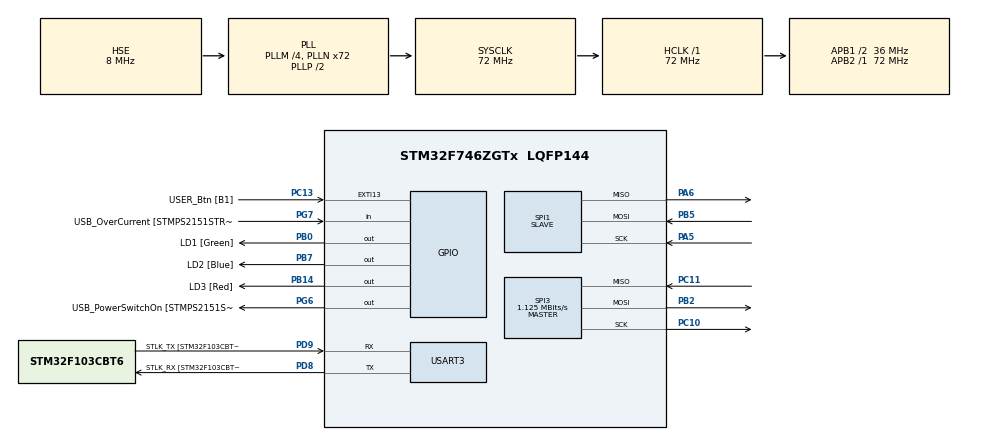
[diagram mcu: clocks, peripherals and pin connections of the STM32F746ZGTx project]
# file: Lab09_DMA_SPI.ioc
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Dma.Request0=SPI1_RX
Dma.Request1=SPI1_TX
Dma.Request2=SPI3_RX
Dma.Request3=SPI3_TX
Dma.SPI1_RX.0.Direction=DMA_PERIPH_TO_MEMORY
Dma.SPI1_RX.0.FIFOMode=DMA_FIFOMODE_DISABLE
Dma.SPI1_RX.0.Instance=DMA2_Stream0
Dma.SPI1_RX.0.MemDataAlignment=DMA_MDATAALIGN_BYTE
Dma.SPI1_RX.0.MemInc=DMA_MINC_ENABLE
Dma.SPI1_RX.0.Mode=DMA_NORMAL
Dma.SPI1_RX.0.PeriphDataAlignment=DMA_PDATAALIGN_BYTE
Dma.SPI1_RX.0.PeriphInc=DMA_PINC_DISABLE
Dma.SPI1_RX.0.Priority=DMA_PRIORITY_LOW
Dma.SPI1_TX.1.Direction=DMA_MEMORY_TO_PERIPH
Dma.SPI1_TX.1.FIFOMode=DMA_FIFOMODE_DISABLE
Dma.SPI1_TX.1.Instance=DMA2_Stream3
Dma.SPI1_TX.1.MemDataAlignment=DMA_MDATAALIGN_BYTE
Dma.SPI1_TX.1.MemInc=DMA_MINC_ENABLE
Dma.SPI1_TX.1.Mode=DMA_NORMAL
Dma.SPI1_TX.1.PeriphDataAlignment=DMA_PDATAALIGN_BYTE
Dma.SPI1_TX.1.PeriphInc=DMA_PINC_DISABLE
Dma.SPI1_TX.1.Priority=DMA_PRIORITY_LOW
Dma.SPI3_RX.2.Direction=DMA_PERIPH_TO_MEMORY
Dma.SPI3_RX.2.FIFOMode=DMA_FIFOMODE_DISABLE
Dma.SPI3_RX.2.Instance=DMA1_Stream0
Dma.SPI3_RX.2.MemDataAlignment=DMA_MDATAALIGN_BYTE
Dma.SPI3_RX.2.MemInc=DMA_MINC_ENABLE
Dma.SPI3_RX.2.Mode=DMA_NORMAL
Dma.SPI3_RX.2.PeriphDataAlignment=DMA_PDATAALIGN_BYTE
Dma.SPI3_RX.2.PeriphInc=DMA_PINC_DISABLE
Dma.SPI3_RX.2.Priority=DMA_PRIORITY_LOW
Dma.SPI3_TX.3.Direction=DMA_MEMORY_TO_PERIPH
Dma.SPI3_TX.3.FIFOMode=DMA_FIFOMODE_DISABLE
Dma.SPI3_TX.3.Instance=DMA1_Stream5
Dma.SPI3_TX.3.MemDataAlignment=DMA_MDATAALIGN_BYTE
Dma.SPI3_TX.3.MemInc=DMA_MINC_ENABLE
Dma.SPI3_TX.3.Mode=DMA_NORMAL
Dma.SPI3_TX.3.PeriphDataAlignment=DMA_PDATAALIGN_BYTE
Dma.SPI3_TX.3.PeriphInc=DMA_PINC_DISABLE
Dma.SPI3_TX.3.Priority=DMA_PRIORITY_LOW
Mcu.Family=STM32F7
Mcu.Name=STM32F746ZGTx
Mcu.Package=LQFP144
NVIC.DMA1_Stream0_IRQn=true\:0\:0\:false\:false\:true\:false\:true\:true
NVIC.DMA1_Stream5_IRQn=true\:0\:0\:false\:false\:true\:false\:true\:true
NVIC.DMA2_Stream0_IRQn=true\:0\:0\:false\:false\:true\:false\:true\:true
NVIC.DMA2_Stream3_IRQn=true\:0\:0\:false\:false\:true\:false\:true\:true
NVIC.PriorityGroup=NVIC_PRIORITYGROUP_4
NVIC.SPI1_IRQn=true\:0\:0\:true\:false\:true\:true\:true\:true
NVIC.SPI3_IRQn=true\:0\:0\:false\:false\:true\:true\:true\:true
PA13.GPIO_Label=TMS
PA13.Mode=Serial_Wire
PA13.Signal=SYS_JTMS-SWDIO
PA14.GPIO_Label=TCK
PA14.Mode=Serial_Wire
PA14.Signal=SYS_JTCK-SWCLK
PA5.Mode=Full_Duplex_Slave
PA5.Signal=SPI1_SCK
PA6.Mode=Full_Duplex_Slave
PA6.Signal=SPI1_MISO
PB0.GPIO_Label=LD1 [Green]
PB0.Signal=GPIO_Output
PB14.GPIO_Label=LD3 [Red]
PB14.Signal=GPIO_Output
PB2.Mode=Full_Duplex_Master
PB2.Signal=SPI3_MOSI
PB3.GPIO_Label=SW0
PB3.Signal=SYS_JTDO-SWO
PB5.Mode=Full_Duplex_Slave
PB5.Signal=SPI1_MOSI
PB7.GPIO_Label=LD2 [Blue]
PB7.Signal=GPIO_Output
PC10.Mode=Full_Duplex_Master
PC10.Signal=SPI3_SCK
PC11.Mode=Full_Duplex_Master
PC11.Signal=SPI3_MISO
PC13.GPIO_Label=USER_Btn [B1]
PC13.Signal=GPXTI13
PC14/OSC32_IN.Mode=LSE-External-Oscillator
PC14/OSC32_IN.Signal=RCC_OSC32_IN
PC15/OSC32_OUT.Mode=LSE-External-Oscillator
PC15/OSC32_OUT.Signal=RCC_OSC32_OUT
PD8.GPIO_Label=STLK_RX [STM32F103CBT6_PA3]
PD8.GPIO_PuPd=GPIO_PULLUP
PD8.Mode=Asynchronous
PD8.Signal=USART3_TX
PD9.GPIO_Label=STLK_TX [STM32F103CBT6_PA2]
PD9.GPIO_PuPd=GPIO_PULLUP
PD9.Mode=Asynchronous
PD9.Signal=USART3_RX
PG6.GPIO_Label=USB_PowerSwitchOn [STMPS2151STR_EN]
PG6.Signal=GPIO_Output
PG7.GPIO_Label=USB_OverCurrent [STMPS2151STR_FAULT]
PG7.Signal=GPIO_Input
PH0/OSC_IN.GPIO_Label=MCO [STM32F103CBT6_PA8]
PH0/OSC_IN.Mode=HSE-External-Clock-Source
PH0/OSC_IN.Signal=RCC_OSC_IN
PH1/OSC_OUT.Mode=HSE-External-Clock-Source
PH1/OSC_OUT.Signal=RCC_OSC_OUT
ProjectManager.HeapSize=0x200
ProjectManager.StackSize=0x400
ProjectManager.TargetToolchain=STM32CubeIDE
RCC.48MHZClocksFreq_Value=24000000
RCC.AHBFreq_Value=72000000
RCC.APB1CLKDivider=RCC_HCLK_DIV2
RCC.APB1Freq_Value=36000000
RCC.APB1TimFreq_Value=72000000
RCC.APB2Freq_Value=72000000
RCC.APB2TimFreq_Value=72000000
RCC.CortexFreq_Value=72000000
RCC.HCLKFreq_Value=72000000
RCC.HSE_VALUE=8000000
RCC.HSI_VALUE=16000000
RCC.PLLM=4
RCC.PLLMUL=RCC_PLL_MUL9
RCC.PLLN=72
RCC.PLLQ=3
RCC.PLLSourceVirtual=RCC_PLLSOURCE_HSE
RCC.PRESCALERUSB=RCC_USBCLKSOURCE_PLL_DIV1_5
RCC.SYSCLKFreq_VALUE=72000000
RCC.SYSCLKSource=RCC_SYSCLKSOURCE_PLLCLK
RCC.SYSCLKSourceVirtual=RCC_SYSCLKSOURCE_PLLCLK
RCC.USBFreq_Value=48000000
RCC.VCOOutputFreq_Value=144000000
SPI1.DataSize=SPI_DATASIZE_8BIT
SPI1.Direction=SPI_DIRECTION_2LINES
SPI1.Mode=SPI_MODE_SLAVE
SPI1.VirtualType=VM_SLAVE
SPI3.BaudRatePrescaler=SPI_BAUDRATEPRESCALER_32
SPI3.CalculateBaudRate=1.125 MBits/s
SPI3.DataSize=SPI_DATASIZE_8BIT
SPI3.Direction=SPI_DIRECTION_2LINES
SPI3.Mode=SPI_MODE_MASTER
SPI3.VirtualType=VM_MASTER
USART3.VirtualMode-Asynchronous=VM_ASYNC
board=NUCLEO-F746ZG

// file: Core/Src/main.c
/* USER CODE BEGIN Header */
/**
  ******************************************************************************
  * @file           : main.c
  * @brief          : Main program body
  ******************************************************************************
  * @attention
  *
  * Copyright (c) 2023 STMicroelectronics.
  * All rights reserved.
  *
  * This software is licensed under terms that can be found in the LICENSE file
  * in the root directory of this software component.
  * If no LICENSE file comes with this software, it is provided AS-IS.
  *
  ******************************************************************************
  */
/* USER CODE END Header */
#include "main.h"
#include "dma.h"
#include "spi.h"
#include "usart.h"
#include "gpio.h"

/* USER CODE BEGIN Includes */
#include "../../rtg/rtg_main.h"
/* USER CODE END Includes */

void SystemClock_Config(void);

int main(void)
{

  /* MCU Configuration--------------------------------------------------------*/

  /* Reset of all peripherals, Initializes the Flash interface and the Systick. */
  HAL_Init();

  /* Configure the system clock */
  SystemClock_Config();

  /* Initialize all configured peripherals */
  MX_GPIO_Init();
  MX_DMA_Init();
  MX_SPI1_Init();
  MX_USART3_UART_Init();
  MX_SPI3_Init();

  /* Infinite loop */
  /* USER CODE BEGIN WHILE */
  rtg_main();
  while (1)
  {
    /* USER CODE END WHILE */

  }
}

void SystemClock_Config(void)
{
  RCC_OscInitTypeDef RCC_OscInitStruct = {0};
  RCC_ClkInitTypeDef RCC_ClkInitStruct = {0};

  /** Configure LSE Drive Capability
  */
  HAL_PWR_EnableBkUpAccess();

  /** Configure the main internal regulator output voltage
  */
  __HAL_RCC_PWR_CLK_ENABLE();
  __HAL_PWR_VOLTAGESCALING_CONFIG(PWR_REGULATOR_VOLTAGE_SCALE3);

  /** Initializes the RCC Oscillators according to the specified parameters
  * in the RCC_OscInitTypeDef structure.
  */
  RCC_OscInitStruct.OscillatorType = RCC_OSCILLATORTYPE_HSE;
  RCC_OscInitStruct.HSEState = RCC_HSE_BYPASS;
  RCC_OscInitStruct.PLL.PLLState = RCC_PLL_ON;
  RCC_OscInitStruct.PLL.PLLSource = RCC_PLLSOURCE_HSE;
  RCC_OscInitStruct.PLL.PLLM = 4;
  RCC_OscInitStruct.PLL.PLLN = 72;
  RCC_OscInitStruct.PLL.PLLP = RCC_PLLP_DIV2;
  RCC_OscInitStruct.PLL.PLLQ = 3;
  if (HAL_RCC_OscConfig(&RCC_OscInitStruct) != HAL_OK)
  {
    Error_Handler();
  }

  /** Initializes the CPU, AHB and APB buses clocks
  */
  RCC_ClkInitStruct.ClockType = RCC_CLOCKTYPE_HCLK|RCC_CLOCKTYPE_SYSCLK
                              |RCC_CLOCKTYPE_PCLK1|RCC_CLOCKTYPE_PCLK2;
  RCC_ClkInitStruct.SYSCLKSource = RCC_SYSCLKSOURCE_PLLCLK;
  RCC_ClkInitStruct.AHBCLKDivider = RCC_SYSCLK_DIV1;
  RCC_ClkInitStruct.APB1CLKDivider = RCC_HCLK_DIV2;
  RCC_ClkInitStruct.APB2CLKDivider = RCC_HCLK_DIV1;

  if (HAL_RCC_ClockConfig(&RCC_ClkInitStruct, FLASH_LATENCY_2) != HAL_OK)
  {
    Error_Handler();
  }
}

void Error_Handler(void)
{
  __disable_irq();
  while (1)
  {
  }
}
